# TLE9273 register map
Vendor: Infineon; File version: 0.1
Registers are 8-bit, read-write, no defined reset value unless marked. A register's access mark holds for its fields unless they carry their own. Offsets are from the block's base; [hi:lo] are bit positions; 'fields as' and 'values as' point back to an identical list.

## CTRL — Control
Base 0x00000000
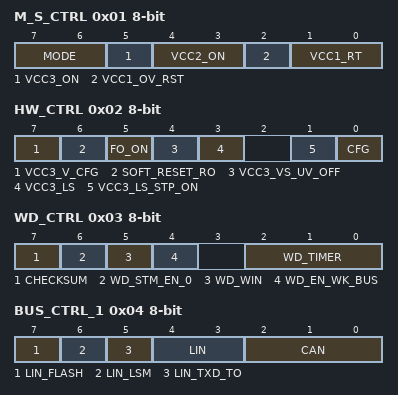
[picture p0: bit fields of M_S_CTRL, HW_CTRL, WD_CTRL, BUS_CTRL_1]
0x01 M_S_CTRL — Mode- and Supply Control
  [7:6] MODE — SBC Mode Control
    0=Normal (SBC Normal Mode); 1=Sleep (SBC Sleep Mode); 2=Stop (SBC Stop Mode); 3=Soft_Reset (SBC Reset: Soft Reset is executed (configuration of RSTN triggering in bit SOFT_RESET_RST))
  [5] VCC3_ON — VCC3 Mode Control
    0=VCC3_off; 1=VCC3_enabled (VCC3 is enabled (as independent voltage regulator))
  [4:3] VCC2_ON — VCC2 Mode Control
    0=VCC2_off; 1=Normal_Mode (VCC2 on in Normal Mode); 2=Normal_and_Stop_Mode (VCC2 on in Normal and Stop Mode); 3=VCC2 always on (except in SBC Init - if not in SBC Development Mode, SBC Restart and Fail-Safe Mode)
  [2] VCC1_OV_RST — VCC1 Over Voltage leading to Restart / Fail-Safe Mode enable
    0=off (VCC1_ OV is set in case of VCC1_OV; no SBC Restart or Fail-Safe is entered for VCC1_OV); 1=activated (VCC1_ OV is set in case of VCC1_OV; depending on the device configuration SBC Restart or SBC Fail-Safe Mode is entered (see );)
  [1:0] VCC1_RT — VCC1 Reset Threshold Control
    0=Vrt1 selected (highest threshold); 1=Vrt2 selected; 2=Vrt3 selected; 3=Vrt4 selected
0x02 HW_CTRL — Hardware Control 0
  [7] VCC3_V_CFG — VCC3 Output Voltage Configuration (if configured as independent voltage regulator)
    0=VCC3_is_same_as_VCC1 (VCC3 has same output voltage as VCC1); 1=3.3V_or_1.8V (VCC3 is configured to either 3.3V or 1.8V (depending on VCC1 derivative))
  [6] SOFT_RESET_RO — Soft Reset Configuration
    0=RO_triggered_by_Soft_Reset (RO will be triggered (pulled low) during a Soft Reset); 1=not_triggered_by_Soft_Reset (no RO trigger during a Soft Reset)
  [5] FO_ON — Failure Output Activation
    0=off (FO not activated by software, FO will be activated by specified failures (see ) (0)); 1=on (FO activated by software (via SPI), only if configured as FO (1))
  [4] VCC3_VS_UV_OFF — VCC3 VS_UV shutdown configuration
    0=VCC3_disabled_at_VS_UV (VCC3 will be disabled automatically at VS_UV); 1=VCC3_enable_below_VS_UV (VCC3 will stay enabled even below VS_UV)
  [3] VCC3_LS — VCC3 Configuration
    0=VCC3_as_stanalone_regulator (VCC3 operating as a stand-alone regulator); 1=in_load_sharing_with_VCC1 (VCC3 in load sharing operation with VCC1)
  [1] VCC3_LS_STP_ON — VCC3 Load Sharing in SBC Stop Mode configuration
    0=VCC3_in_LS_disabled (VCC3 in LS configuration during SBC Stop Mode and highpower mode: disabled); 1=VCC3_in_LS_enabled (VCC3 in LS configuration during SBC Stop Mode and highpower mode: enabled)
  [0] CFG — Configuration Select (see also )
    0=after_2nd (Depending on hardware configuration, SBC Restart or Fail-Safe Mode is reached after the 2. watchdog trigger failure (=default) - Config 3/4); 1=after_1st (Depending on hardware configuration, SBC Restart or Fail-Safe Mode is reached after the 1. watchdog trigger failure - Config 1/2)
0x03 WD_CTRL — Watchdog Control
  [7] CHECKSUM — Watchdog Setting Check Sum Bit
    0=Counts as 0 for checksum calculation; 1=Counts as 1 for checksum calculation
  [6] WD_STM_EN_0 — Watchdog Deactivation during Stop Mode, bit 0 ()
    0=active (Watchdog is active in Stop Mode); 1=off (Watchdog is deactivated in Stop Mode)
  [5] WD_WIN — Watchdog Type Selection
    0=Time-out (Watchdog works as a Time-Out watchdog); 1=Window (Watchdog works as a Window watchdog)
  [4] WD_EN_WK_BUS — Watchdog Enable after Bus (CAN) Wake in SBC Stop Mode
    0=off (Watchdog will not start after a CAN wake); 1=on (Watchdog starts with a long open window after CAN Wake)
  [2:0] WD_TIMER — Watchdog Timer Period
    0=10ms; 1=20ms; 2=50ms; 3=100ms; 4=200ms; 5=500ms; 6=1s (1000ms); 7=10s (10000ms)
0x04 BUS_CTRL_1 — Bus Control
  [7] LIN_FLASH — LIN Flash Programming Mode
    0=slope_control_active (Slope control mechanism active); 1=deactive_at_115kBaud (Deactivation of slope control for baud rates up to 115kBaud)
  [6] LIN_LSM — LIN Low-Slope Mode Selection
    0=normal_mode (LIN Normal-Mode is activated); 1=low_slope_mode (LIN Low-Slope Mode (10.4kBaud) activated)
  [5] LIN_TXD_TO — LIN TXD Time-Out Control
    0=TXD_time_out_disabled (TXD Time-Out feature disabled); 1=TXD_time_out_enabled (TXD Time-Out feature enabled)
  [4:3] LIN — LIN-Module Modes
    0=off (LIN OFF); 1=weak_capable (LIN is wake capable); 2=receive_only (LIN Receive Only Mode); 3=normal (LIN Normal Mode)
  [2:0] CAN — HS-CAN Module Modes (CAN_2 is rw type)
    0=off (CAN OFF); 1=wake_capable (CAN is wake capable); 2=receive_only (CAN Receive Only Mode (no SWK)); 3=normal (CAN Normal Mode (no SWK)); 4=off (CAN OFF); 5=wake_capable_(SWK) (CAN is wake capable with SWK); 6=receive_only_(SWK) (CAN Receive Only Mode with SWK); 7=normal_(SWK) (CAN Normal Mode with SWK)
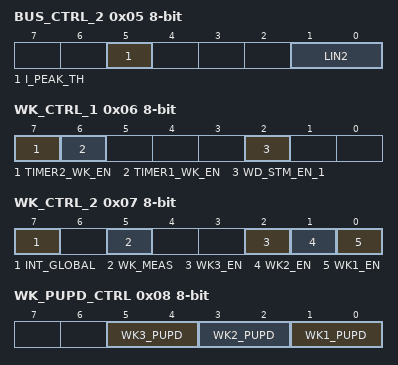
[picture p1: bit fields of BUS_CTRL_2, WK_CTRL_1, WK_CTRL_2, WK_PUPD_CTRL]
0x05 BUS_CTRL_2 — Bus Control
  [5] I_PEAK_TH — VCC1 Active Peak Threshold Selection
    0=low_active_threshold (low VCC1 active peak threshold selected (ICC1,peak_1)); 1=low_active_threshold (higher VCC1 active peak threshold selected (ICC1,peak_2))
  [1:0] LIN2 — LIN2-Module Modes
    0=off (LIN2 OFF); 1=wake_capable (LIN2 is wake capable); 2=receive_only (LIN2 Receive Only Mode); 3=normal (LIN2 Normal Mode)
0x06 WK_CTRL_1 — Internal Wake Input Control
  [7] TIMER2_WK_EN — Timer2 Wake Source Control (for cyclic wake)
    0=disabled (Timer2 wake disabled); 1=enabled (Timer2 is enabled as a wake source)
  [6] TIMER1_WK_EN — Timer1 Wake Source Control (for cyclic wake)
    values as TIMER2_WK_EN
  [2] WD_STM_EN_1 — Watchdog Deactivation during Stop Mode, bit 1 ()
    0=WD_active_in_stop_mode (Watchdog is active in Stop Mode); 1=off (Watchdog is deactivated in Stop Mode)
0x07 WK_CTRL_2 — External Wake Source Control
  [7] INT_GLOBAL — Global Interrupt Configuration (see also )
    0=wake_only (Only wake sources trigger INTN (default)); 1=all_status_bits (All status information register bits will trigger INTN (including all wake sources))
  [5] WK_MEAS — Wake / Voltage Sensing Selection (see also )
    0=Wake functionality enabled for WK; 1=Voltage sensing functionality enabled, no wake-up events are generated
  [2] WK3_EN — WK3 Wake Source Control
    0=disabled (WK3 wake disabled); 1=enabled (WK3 is enabled as a wake source)
  [1] WK2_EN — WK2 Wake Source Control
    0=disabled (WK2 wake disabled); 1=enabled (WK2 is enabled as a wake source)
  [0] WK1_EN — WK1 Wake Source Control
    0=disabled (WK1 wake disabled); 1=enabled (WK1 is enabled as a wake source)
0x08 WK_PUPD_CTRL — Wake Input Level Control
  [all] fields
    0=none (No pull-up / pull-down selected); 1=Pull-down resistor selected; 2=Pull-up resistor selected; 3=Automatic switching to pull-up or pull-down
  [5:4] WK3_PUPD — WK3 Pull-Up / Pull-Down Configuration
  [3:2] WK2_PUPD — WK2 Pull-Up / Pull-Down Configuration
  [1:0] WK1_PUPD — WK1 Pull-Up / Pull-Down Configuration
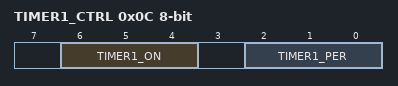
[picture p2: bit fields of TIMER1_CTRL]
0x0C TIMER1_CTRL — Timer1 Control and Selection
  [6:4] TIMER1_ON — Timer1 On-Time Configuration
    0=OFF / Low (timer not running, HSx output is low); 1=0.1ms on-time; 2=0.3ms on-time; 3=1.0ms on-time; 4=10ms on-time; 5=20ms on-time; 6=OFF / HIGH (timer not running, HSx output is high)
  [2:0] TIMER1_PER — Timer1 Period Configuration
    0=10ms; 1=20ms; 2=50ms; 3=100ms; 4=200ms; 5=1s; 6=2s
0x1E SYS_STATUS_CTRL — System Status Control
  [7:0] SYS_STAT — System Status Control Byte (bit0=LSB; bit7=MSB)
